AUTOSAR XML (schema 4-3-0)
package /ComponentTypes
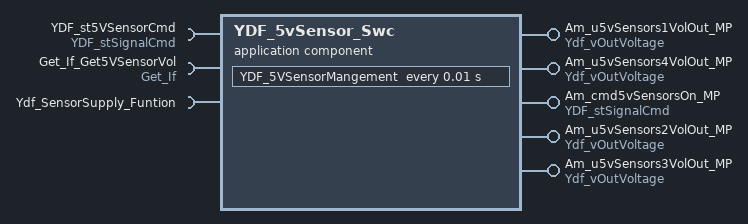
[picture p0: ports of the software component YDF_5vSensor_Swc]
  application sw component type YDF_5vSensor_Swc
    require port YDF_st5VSensorCmd: nonqueued-receiver-com-spec{data-element=SignalCmd, init-value=0}, required-interface=YDF_stSignalCmd
    provide port Am_u5vSensors1VolOut_MP: nonqueued-sender-com-spec{data-element=OutVoltage, init-value=0}, provided-interface=Ydf_vOutVoltage
    provide port Am_u5vSensors4VolOut_MP: nonqueued-sender-com-spec{data-element=OutVoltage, init-value=0}, provided-interface=Ydf_vOutVoltage
    provide port Am_cmd5vSensorsOn_MP: nonqueued-sender-com-spec{data-element=SignalCmd, init-value=0}, provided-interface=YDF_stSignalCmd
    require port Get_If_Get5VSensorVol: required-interface=Get_If
      required-com-specs:
        Get_Ad_Result
        Get_io_inResult
        Get_BTS_OutResult
        Get_CAN_ActiveInf
        Icu_17_GtmCcu6_PWMIN_CH{1..4}
        Icu_17_GtmCcu6_PWMIN_PWMSCB1
        Icu_17_GtmCcu6_PWMIN_PWMSCB2
        Icu_17_GtmCcu6_PWMIN_LAMPSCB1
        Icu_17_GtmCcu6_PWMIN_LAMPSCB2
        Get_Bottom_Ver
        Get_SentData
        Get_Level_OutResult
        Get_PwmOrLevel_OutResult
        Get_Motor_OutResult
    provide port Am_u5vSensors2VolOut_MP: nonqueued-sender-com-spec{data-element=OutVoltage, init-value=0}, provided-interface=Ydf_vOutVoltage
    provide port Am_u5vSensors3VolOut_MP: nonqueued-sender-com-spec{data-element=OutVoltage, init-value=0}, provided-interface=Ydf_vOutVoltage
    require port Ydf_SensorSupply_Funtion: required-com-specs=[SensorSupply3_5v_OUT_Enable, SensorSupply4_5v_OUT_Enable], required-interface=Ydf_SensorSupply_Funtion
    behavior YDF_5vSensor_Swc_InternalBehavior
      timing event TMT_YDF_5VSensorMangement: start-on-event=YDF_5VSensorMangement, period=0.01
      runnable YDF_5VSensorMangement
        data-receive-point-by-arguments:
          access REC_YDF_stSignalCmd_SignalCmd: accessed-variable=YDF_st5VSensorCmd.SignalCmd
        data-send-points:
          5 x access:
            SEND_Am_u5vSensors1VolOut_MP_OutVoltage: accessed-variable=Am_u5vSensors1VolOut_MP.OutVoltage
            SEND_Am_u5vSensors4VolOut_MP_OutVoltage: accessed-variable=Am_u5vSensors4VolOut_MP.OutVoltage
            SEND_Am_cmd5vSensorsOn_MP_SignalCmd: accessed-variable=Am_cmd5vSensorsOn_MP.SignalCmd
            SEND_Am_u5vSensors2VolOut_MP_OutVoltage: accessed-variable=Am_u5vSensors2VolOut_MP.OutVoltage
            SEND_Am_u5vSensors3VolOut_MP_OutVoltage: accessed-variable=Am_u5vSensors3VolOut_MP.OutVoltage
        sync call SC_Get_If_Get5VSensorVol_Get_Ad_Result: operation=Get_If_Get5VSensorVol.Get_Ad_Result
        sync call SC_Ydf_SensorSupply_Funtion_SensorSupply3_5v_OUT_Enable: operation=Ydf_SensorSupply_Funtion.SensorSupply3_5v_OUT_Enable
        sync call SC_Ydf_SensorSupply_Funtion_SensorSupply4_5v_OUT_Enable: operation=Ydf_SensorSupply_Funtion.SensorSupply4_5v_OUT_Enable
  swc implementation YDF_5vSensor_Swc_Implementation: behavior=YDF_5vSensor_Swc_InternalBehavior
